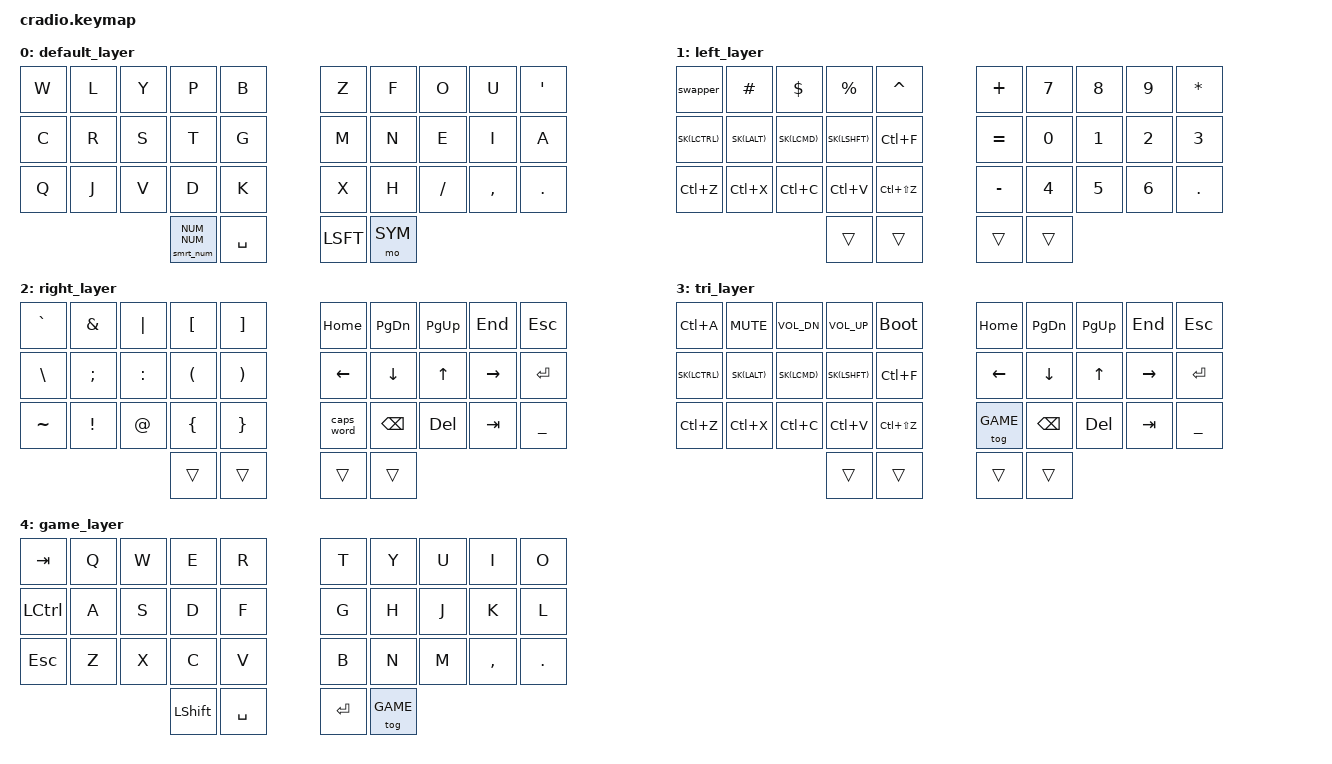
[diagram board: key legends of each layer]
// Copyright (c) 2022 The ZMK Contributors
// SPDX-License-Identifier: MIT

#include <behaviors.dtsi>
#include <dt-bindings/zmk/keys.h>
#include <dt-bindings/zmk/bt.h>
#include <dt-bindings/zmk/dynamic-macros.h>
#include "helper.h"
#include "keypos_34keys.h"

#define XXX &none
#define ___ &trans

#define BASE 0
#define NUM 1
#define SYM 2
#define UTIL 3
#define GAME 4

#define MO(LAYER) &mo_tap LAYER F24

// Keep sticky keys active for a long time so they effectively do not time out
#define STICKY_KEY_TIMEOUT 60000

&caps_word {  
    /delete-property/ ignore-modifiers; // mods deactivate, requires PR #1451
    /delete-property/ ignore-numbers;
    continue-list = <BACKSPACE ENTER DELETE UNDERSCORE MINUS>;
};
&num_word { 
    layers = <NUM>; // requires PR #1441
    continue-list = <BACKSPACE ENTER DELETE UNDERSCORE MINUS PLUS ASTRK EQUAL FSLH DOT LPAR RPAR HASH DLLR PRCNT CARET LEFT RIGHT UP DOWN>;
};

&key_repeat {
    usage-pages = <HID_USAGE_KEY HID_USAGE_CONSUMER>; // repeat all keys
};

// Alt+Tab swapper, requires PR #1366
ZMK_BEHAVIOR(swapper, tri_state,
    bindings = <&kt LALT>, <&kp TAB>, <&kt LALT>;
    ignored-key-positions = <13>; // shift-alt-tab 
)

/* ------------------------------- mod-morphs ------------------------------- */
// tap: comma | shift + tap: semicolon 
ZMK_BEHAVIOR(comma_morph, mod_morph,
    mods = <(MOD_LSFT|MOD_RSFT)>;
    bindings = <&kp COMMA>, <&kp SEMICOLON>;
)
// tap: dot | shift + tap: colon 
ZMK_BEHAVIOR(dot_morph, mod_morph,
    bindings = <&kp DOT>, <&kp COLON>;
    mods = <(MOD_LSFT|MOD_RSFT)>;
)
// tap: qmark | shift + tap: excl
ZMK_BEHAVIOR(qmark_morph, mod_morph,
    bindings = <&kp QMARK>, <&kp EXCL>;
    mods = <(MOD_LSFT|MOD_RSFT)>;
)

// tap: space | shift + tap: dot -> space -> sticky shift
ZMK_BEHAVIOR(spc_morph, mod_morph,
    bindings = <&kp SPACE>, <&dot_spc>;
    mods = <(MOD_LSFT|MOD_RSFT)>;
)
ZMK_BEHAVIOR(dot_spc, macro,
    wait-ms = <5>;
    tap-ms = <5>;
    bindings = <&dot_morph_cancel &kp SPACE &sk LSFT>;
)
ZMK_BEHAVIOR(dot_morph_cancel, mod_morph,
    bindings = <&kp DOT>, <&kp DOT>;
    mods = <(MOD_LSFT|MOD_RSFT)>;
)

&sk { // sticky-key
    release-after-ms = <3000>;  // release after timeout
    quick-release;              // no double capitalization when rolling ke
    ignore-modifiers;
    lazy;
};
ZMK_BEHAVIOR(sk_no_lazy, sticky_key, // sticky-key without lazy
    bindings = <&kp>;
    release-after-ms = <3000>;  // release after timeout
    quick-release;              // no double capitalization when rolling keys
    ignore-modifiers;
)
&sl { // sticky-layer 
    release-after-ms = <500>;  // release after timeout
    // This is useful for enabling a layer and then pressing a bunch of sticky keys without leaving the layer. 
    // However, this breaks tapping sl+control+key because it does not exit the layer.
    // ignore-modifiers;
};

// all sticky keys are sticky when tapped, but momentary when held. 
// this allows for rolling layer keys, and accessing modifiers on base, while not getting in the way.
// this behavior is especially useful for use with a mouse because sticky odifiers don't linger
#define STICKY_TAP_MS 200

// tap: sticky-mod | hold: mod
#define SK(mod) &sk_mod mod mod
ZMK_BEHAVIOR(sk_mod, hold_tap,
    flavor = "balanced"; // balanced because we want to consider as tap when rolling
    tapping-term-ms = <STICKY_TAP_MS>; 
    bindings = <&kp>, <&sk>; 
    hold-while-undecided; // requires pr
)
// for GUI/ALT, we don't want to trigger a tap, so we disable hold while undecided
#define SK_LGUI &sk_mod_gui LGUI LGUI 
#define SK_LALT &sk_mod_gui LALT LALT 
ZMK_BEHAVIOR(sk_mod_gui, hold_tap,
    flavor = "balanced"; // balanced because we want to consider as tap when rolling
    tapping-term-ms = <STICKY_TAP_MS>; 
    bindings = <&kp>, <&sk>; 
)

// tap: sticky-shift | hold: shift | shift + tap / double-tap: caps-word 
#define SK_SHFT &sk_shft LSFT LSFT
ZMK_BEHAVIOR(sk_shft, hold_tap,
    flavor = "balanced"; 
    tapping-term-ms = <STICKY_TAP_MS>; 
    bindings = <&kp>, <&smrt_shft_morph>; 
    hold-while-undecided;
) 
ZMK_BEHAVIOR(smrt_shft_morph, mod_morph,
    mods = <(MOD_LSFT)>; // shift + tap: caps word
    bindings = <&kp LSFT>, <&caps_word>; 
) 

// tap: sticky-layer | hold: layer
#define SMRT_SYM &smrt_layer SYM SYM
#define SMRT_FUN &smrt_layer FUN FUN
ZMK_BEHAVIOR(smrt_layer, hold_tap,
    flavor = "hold-preferred"; // in most cases we want to avoid taps
    tapping-term-ms = <STICKY_TAP_MS>; 
    bindings = <&mo>, <&sl>; 
) 

// ~~tap: sticky-num~~ | hold: num | double-tap: num-word | triple-tap: num-lock
#define SMRT_NUM &smrt_num NUM NUM
ZMK_BEHAVIOR(smrt_num, hold_tap,
    flavor = "hold-preferred"; 
    tapping-term-ms = <STICKY_TAP_MS>; 
    bindings = <&mo>, <&num_dance>; 
) 
ZMK_BEHAVIOR(num_dance, tap_dance,
    tapping-term-ms = <300>; 
    bindings = <&mo NUM>, <&num_word>, <&tog NUM>; // todo: to or tog?
)
// tap: comma | shift + tap: semicolon 
ZMK_BEHAVIOR(comma_morph, mod_morph,
    mods = <(MOD_LSFT|MOD_RSFT)>;
    bindings = <&kp COMMA>, <&kp SEMICOLON>;
)
// tap: dot | shift + tap: colon 
ZMK_BEHAVIOR(dot_morph, mod_morph,
    bindings = <&kp DOT>, <&kp COLON>;
    mods = <(MOD_LSFT|MOD_RSFT)>;
)


#define S_UNDO &kp LC(Z)
#define S_CUT &kp LC(X)
#define S_COPY &kp LC(C)
#define S_PASTE &kp LC(V)
#define S_REDO &kp LC(LS(Z))

/ {
    behaviors {
        ht: hold_tap {
            label = "hold_tap";
            compatible = "zmk,behavior-hold-tap";
            #binding-cells = <2>;
            flavor = "tap-preferred";
            tapping-term-ms = <220>;
            quick-tap-ms = <150>;
            global-quick-tap;
            bindings = <&kp>, <&kp>;
        };
        nk: not_so_sticky_key {
            compatible = "zmk,behavior-hold-tap";
            label = "NOT_SO_STICKY_KEY";
            #binding-cells = <2>;
            tapping_term_ms = <200>;
            flavor = "tap-preferred";
            bindings = <&kp>, <&sk>;
        };
        skq: sticky_key_quick_release {
            compatible = "zmk,behavior-sticky-key";
            label = "STICKY_KEY_QUICK_RELEASE";
            #binding-cells = <1>;
            bindings = <&kp>;
            quick-release;
            release-after-ms = <STICKY_KEY_TIMEOUT>;
        };
        // A hold-tap that activates without delay (like `&mo`)
        mo_tap: mo_with_tap {
          compatible = "zmk,behavior-hold-tap";
          label = "MO_WITH_TAP";
          #binding-cells = <2>;
          tapping_term_ms = <0>;
          retro-tap;
          flavor = "hold-preferred";
          bindings = <&mo>, <&kp>;
        };
    };

    conditional_layers {
        compatible = "zmk,conditional-layers";
        tri_layer {
            if-layers = <1 2>;
            then-layer = <3>;
        };
    };
    macros {
        right_arrow: right_arrow {
            label = "ZM_right_arrow";
            compatible = "zmk,behavior-macro";
            #binding-cells = <0>;
            bindings
                = <&macro_tap &kp MINUS &kp GT>
                ;
        };
    };
    
    keymap {
        compatible = "zmk,keymap";
        default_layer {
            bindings = <
            &kp W      &kp L      &kp Y      &kp P      &kp B          &kp Z      &kp F      &kp O      &kp U      &kp SQT
            &kp C       &kp R      &kp S       &kp T     &kp G          &kp M      &kp N       &kp E     &kp I       &kp A
            &kp Q      &kp J      &kp V      &kp D      &kp K          &kp X      &kp H      &kp FSLH  &kp COMMA    &kp DOT
                                             SMRT_NUM   &kp SPACE     &kp LSFT  &mo SYM
            >;
        };

        left_layer {
            bindings = <
        
                                 &swapper  &kp HASH  &kp DLLR  &kp PRCNT   &kp CARET       &kp PLUS   &kp N7     &kp N8     &kp N9    &kp ASTRK
         
            SK(LCTRL) SK(LALT)  SK(LCMD)  SK(LSHFT)  &kp LC(F)       &kp EQUAL     &kp N0    &kp N1    &kp N2     &kp N3
      
                                S_UNDO  S_CUT  S_COPY  S_PASTE  S_REDO      &kp MINUS   &kp N4     &kp N5     &kp N6     &kp DOT
    
                                                                    &trans     &trans       &trans     &trans
        
            >;
        };

        right_layer {
            bindings = <
        
            &kp GRAVE  &kp AMPS   &kp PIPE   &kp LBKT   &kp RBKT        &kp HOME  &kp PG_DN  &kp PG_UP   &kp END   &kp ESC
        
            &kp BSLH   &kp SEMI  &kp COLON   &kp LPAR   &kp RPAR         &kp LEFT  &kp DOWN   &kp UP     &kp RIGHT   &kp ENTER
       
            &kp TILDE  &kp EXCL     &kp AT  &kp LBRC   &kp RBRC         &caps_word   &kp BSPC   &kp DEL    &kp TAB   &kp UNDER
       
                                             &trans     &trans         &trans     &trans
        
            >;
        };

        tri_layer {
            bindings = <
            &kp LC(A) &kp C_MUTE &kp C_VOL_DN &kp C_VOL_UP &bootloader       &kp HOME  &kp PG_DN  &kp PG_UP   &kp END   &kp ESC
            SK(LCTRL) SK(LALT)  SK(LCMD)  SK(LSHFT)  &kp LC(F)               &kp LEFT  &kp DOWN   &kp UP     &kp RIGHT   &kp ENTER
            S_UNDO  S_CUT  S_COPY  S_PASTE  S_REDO                           &tog GAME   &kp BSPC   &kp DEL    &kp TAB   &kp UNDER
                                             &trans     &trans               &trans     &trans
            >;
        };

        game_layer {
          bindings = <
            &kp TAB   &kp Q     &kp W     &kp E     &kp R        &kp T     &kp Y     &kp U     &kp I      &kp O
            &kp LCTRL &kp A     &kp S     &kp D     &kp F        &kp G     &kp H     &kp J     &kp K      &kp L
            &kp ESC &kp Z     &kp X     &kp C     &kp V        &kp B     &kp N     &kp M     &kp COMMA  &kp DOT
                                   &kp LSHFT  &kp SPACE           &kp ENTER  &tog GAME
          >;
        };
    };

};
// ╭─────────────────────┬─────────────────────╮
// │ LT4 LT3 LT2 LT1 LT0 │ RT0 RT1 RT2 RT3 RT4 │
// │ LM4 LM3 LM2 LM1 LM0 │ RM0 RM1 RM2 RM3 RM4 │
// │ LB4 LB3 LB2 LB1 LB0 │ RB0 RB1 RB2 RB3 RB4 │
// ╰───────╮ LH2 LH1 LH0 │ RH0 RH1 RH2 ╭───────╯
//         ╰─────────────┴─────────────╯
#undef COMBO_HOOK
#define COMBO_HOOK global-quick-tap-ms = <50>;
// combos on every layer
#define LAYER_COMBO(name, keypos, bindings, layer) ZMK_COMBO(name, bindings, keypos, layer, 50)
#define GLOBAL_COMBO(name, keypos, bindings) LAYER_COMBO(name, keypos, bindings, ALL)
GLOBAL_COMBO(numl, RB3 RB4, &num_word)
GLOBAL_COMBO(dot_spc, LH0 RH0, &dot_spc)
GLOBAL_COMBO(r_arrow, RB1 RB2, &right_arrow)

// vertical sfb combos
#define VERTICAL_COMBO(keypos, key1, key2) \
    ZMK_BEHAVIOR(macro_vertical_combo_##key1##key2, macro, \
        wait-ms = <20>; \
        tap-ms = <20>; \
        bindings \
            = <&macro_tap &kp key1> \
            , <&macro_press &kp key2> \
            , <&macro_pause_for_release> \
            , <&macro_release &kp key2> \
            ; \
    ) \
    / { \
        combos { \
            compatible = "zmk,combos"; \
            combo_vertical_combo_##key1##key2 { \
                timeout-ms = <40>; \
                layers = <BASE>; \
                key-positions = <keypos>; \
                bindings = <&macro_vertical_combo_##key1##key2>; \
                slow-release;  \
            }; \
        }; \
    };

// disambiguate mashing SFBs
VERTICAL_COMBO(LT4 LM4, W, C)
VERTICAL_COMBO(LT3 LM3, R, L)
VERTICAL_COMBO(LT2 LM2, Y, S)
VERTICAL_COMBO(LT1 LM1, P, T)
VERTICAL_COMBO(LT0 LM0, G, B)

VERTICAL_COMBO(LM0 LB0, K, G)
VERTICAL_COMBO(LM1 LB1, T, D)
VERTICAL_COMBO(LM2 LB2, V, S)
//VERTICAL_COMBO(LM3 LB3, R, J)
VERTICAL_COMBO(LM4 LB4, C, Q)

VERTICAL_COMBO(LM1 LM0, G, T)
VERTICAL_COMBO(LT1 LT0, P, B)
VERTICAL_COMBO(LB1 LB0, D, K)

VERTICAL_COMBO(RM1 RM0, M, N)
//VERTICAL_COMBO(RT1 RT0, Z, F)
VERTICAL_COMBO(RB1 RB0, X, H)

VERTICAL_COMBO(RT4 RM4, A, APOS)
VERTICAL_COMBO(RT3 RM3, U, I)
VERTICAL_COMBO(RT2 RM2, E, O)
VERTICAL_COMBO(RT1 RM1, N, F)
VERTICAL_COMBO(RT0 RM0, Z, M)

//VERTICAL_COMBO(RM0 RB0, X, M)
VERTICAL_COMBO(RM1 RB1, N, H)
//VERTICAL_COMBO(RM2 RB2, FSLH, E)
VERTICAL_COMBO(RM3 RB3, I, COMMA)
VERTICAL_COMBO(RM4 RB4, A, DOT)
